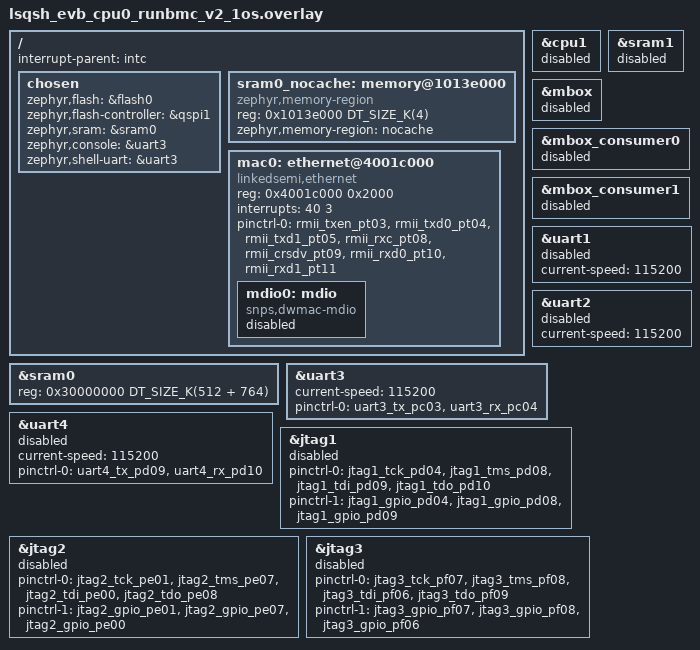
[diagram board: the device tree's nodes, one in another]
/*
 * Copyright (c) 2024, linkedsemi
 * SPDX-License-Identifier: Apache-2.0
 */

#include "lsqsh_evb_pinctrl_runbmc_v2.dtsi"

/delete-node/ &sram0_nocache;
/delete-node/ &mac0;
/ {
    interrupt-parent = <&intc>;

    chosen {
        zephyr,flash = &flash0;
        zephyr,flash-controller = &qspi1;
        zephyr,sram = &sram0;
        zephyr,console = &uart3;
        zephyr,shell-uart = &uart3;
    };

    sram0_nocache: memory@1013e000{
        compatible = "zephyr,memory-region", "mmio-sram";
        reg = <0x1013e000 DT_SIZE_K(4)>;
        device_type = "memory";
        zephyr,memory-region = "nocache";
    };

    mac0: ethernet@4001c000 {
        compatible = "linkedsemi,ethernet", "snps,designware-ethernet";
        reg = <0x4001c000 0x2000>;
        interrupts = <40 3>;
        status = "disabled";

        mdio0: mdio {
            compatible = "snps,dwmac-mdio";
            #address-cells = <1>;
            #size-cells = <0>;
            status = "disabled";
        };
    };
};

&cpu1 {
    status = "disabled";
};

&sram0 {
    reg = <0x30000000 DT_SIZE_K(512 + 764)>;
};

&sram1 {
    status = "disabled";
};

&mbox {
    status = "disabled";
};

&mbox_consumer0 {
    status = "disabled";
};

&mbox_consumer1 {
    status = "disabled";
};

&uart1 {
    current-speed = <115200>;
    status = "disabled";
};

&uart2 {
    current-speed = <115200>;
    status = "disabled";
};

&uart3 {
    current-speed = <115200>;
    pinctrl-0 = <&uart3_tx_pc03 &uart3_rx_pc04>;
    pinctrl-names = "default";
    status = "okay";
};

&uart4 {
    current-speed = <115200>;
    pinctrl-0 = <&uart4_tx_pd09 &uart4_rx_pd10>;
    pinctrl-names = "default";
    status = "disabled";
};

// &i2c2 {
//     pinctrl-0 = <&i2c2_scl_pb03 &i2c2_sda_pb04>;
//     pinctrl-names = "default";
//     status = "okay";

//     eeprom2: eeprom@76 {
//         compatible = "zephyr,i2c-target-eeprom";
//         reg = <0x76>;
//         size = <256>;
//         status = "okay";
//     };
// };

// &i2c3 {
//     pinctrl-0 = <&i2c3_scl_pc13 &i2c3_sda_pc11>;
//     pinctrl-names = "default";
//     status = "okay";

//     eeprom3: eeprom@76 {
//         compatible = "zephyr,i2c-target-eeprom";
//         reg = <0x76>;
//         size = <256>;
//         status = "okay";
//     };
// };

// &i2c4 {
//     pinctrl-0 = <&i2c4_scl_pd00 &i2c4_sda_pd01>;
//     pinctrl-names = "default";
//     status = "okay";

//     eeprom4: eeprom@76 {
//         compatible = "zephyr,i2c-target-eeprom";
//         reg = <0x76>;
//         size = <256>;
//         status = "okay";
//     };
// };

// &i2c5 {
//     pinctrl-0 = <&i2c5_scl_pe07 &i2c5_sda_pe08>;
//     pinctrl-names = "default";
//     status = "okay";

//     eeprom5: eeprom@76 {
//         compatible = "zephyr,i2c-target-eeprom";
//         reg = <0x76>;
//         size = <256>;
//         status = "okay";
//     };
// };

// &i2c6 {
//     pinctrl-0 = <&i2c6_scl_pf07 &i2c6_sda_pf08>;
//     pinctrl-names = "default";
//     status = "okay";

//     eeprom6: eeprom@76 {
//         compatible = "zephyr,i2c-target-eeprom";
//         reg = <0x76>;
//         size = <256>;
//         status = "okay";
//     };
// };

// &i2c7 {
//     pinctrl-0 = <&i2c7_scl_pk15 &i2c7_sda_pk14>;
//     pinctrl-names = "default";
//     status = "okay";

//     eeprom7: eeprom@76 {
//         compatible = "zephyr,i2c-target-eeprom";
//         reg = <0x76>;
//         size = <256>;
//         status = "okay";
//     };
// };

// &i2c10 {
//     pinctrl-0 = <&i2c10_scl_pj03 &i2c10_sda_pj02>;
//     pinctrl-names = "default";
//     status = "okay";

//     eeprom10: eeprom@76 {
//         compatible = "zephyr,i2c-target-eeprom";
//         reg = <0x76>;
//         size = <256>;
//         status = "okay";
//     };
// };

// &i2c11 {
//     pinctrl-0 = <&i2c11_scl_pn09 &i2c11_sda_pn08>;
//     pinctrl-names = "default";
//     status = "okay";

//     eeprom11: eeprom@76 {
//         compatible = "zephyr,i2c-target-eeprom";
//         reg = <0x76>;
//         size = <256>;
//         status = "okay";
//     };
// };

// &i2c12 {
//     pinctrl-0 = <&i2c12_scl_pn13 &i2c12_sda_pn14>;
//     pinctrl-names = "default";
//     status = "okay";

//     eeprom12: eeprom@76 {
//         compatible = "zephyr,i2c-target-eeprom";
//         reg = <0x76>;
//         size = <256>;
//         status = "okay";
//     };
// };

// &i2c13 {
//     pinctrl-0 = <&i2c13_scl_pq00 &i2c13_sda_pq01>;
//     pinctrl-names = "default";
//     status = "okay";

//     eeprom13: eeprom@76 {
//         compatible = "zephyr,i2c-target-eeprom";
//         reg = <0x76>;
//         size = <256>;
//         status = "okay";
//     };
// };

// &i2c14 {
//     pinctrl-0 = <&i2c14_scl_pq03 &i2c14_sda_pq02>;
//     pinctrl-names = "default";
//     status = "okay";

//     eeprom14: eeprom@76 {
//         compatible = "zephyr,i2c-target-eeprom";
//         reg = <0x76>;
//         size = <256>;
//         status = "okay";
//     };
// };

// /*
//     smbus
// */

// &smbus_ali_11_runbmc_i2c8_fpga_i2c2 {
//     status = "okay";
// };

// &smbus_ali_14_runbmc_i2c4_fpga_i2c3 {
//     status = "okay";
// };

// &smbus_ali_9_runbmc_i2c12_fpga_i2c4 {
//     status = "okay";
// };

// &smbus_ali_16_runbmc_i2c14_fpga_i2c5 {
//     status = "okay";
// };

// &smbus_ali_7_runbmc_i2c15_fpga_i2c6 {
//     status = "okay";
// };

// &smbus_ali_13_runbmc_i2c7_fpga_i2c7 {
//     status = "okay";
// };

// &smbus_ali_10_runbmc_i2c16_fpga_i2c10 {
//     status = "okay";
// };

// &smbus_ali_8_runbmc_i2c11_fpga_i2c11 {
//     status = "okay";
// };

// &smbus_ali_15_runbmc_i2c2_fpga_i2c12 {
//     status = "okay";
// };

// &smbus_ali_5_runbmc_i2c9_fpga_i2c13 {
//     status = "okay";
// };

// &smbus_ali_6_runbmc_i2c10_fpga_i2c14 {
//     status = "okay";
// };

&jtag1 {
    pinctrl-0 = <&jtag1_tck_pd04 &jtag1_tms_pd08 &jtag1_tdi_pd09 &jtag1_tdo_pd10>;
    pinctrl-1 = <&jtag1_gpio_pd04 &jtag1_gpio_pd08 &jtag1_gpio_pd09>;
    pinctrl-names = "default", "priv_start";
    status = "disabled";
};

&jtag2 {
    pinctrl-0 = <&jtag2_tck_pe01 &jtag2_tms_pe07 &jtag2_tdi_pe00 &jtag2_tdo_pe08>;
    pinctrl-1 = <&jtag2_gpio_pe01 &jtag2_gpio_pe07 &jtag2_gpio_pe00>;
    pinctrl-names = "default", "priv_start";
    status = "disabled";
};

&jtag3 {
    pinctrl-0 = <&jtag3_tck_pf07 &jtag3_tms_pf08 &jtag3_tdi_pf06 &jtag3_tdo_pf09>;
    pinctrl-1 = <&jtag3_gpio_pf07 &jtag3_gpio_pf08 &jtag3_gpio_pf06>;
    pinctrl-names = "default", "priv_start";
    status = "disabled";
};

&mac0 {
    pinctrl-0 = <&rmii_txen_pt03
                &rmii_txd0_pt04
                &rmii_txd1_pt05
                &rmii_rxc_pt08
                &rmii_crsdv_pt09
                &rmii_rxd0_pt10
                &rmii_rxd1_pt11>;
    pinctrl-names = "default";
    status = "okay";
};
